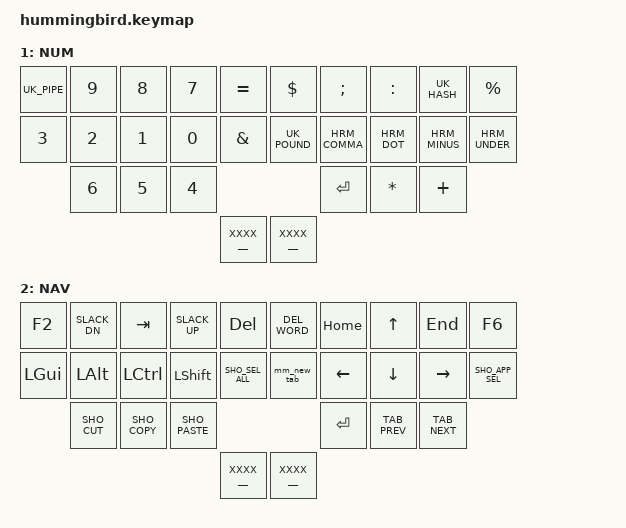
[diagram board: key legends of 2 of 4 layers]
/*
 * Copyright (c) 2020 The ZMK Contributors
 *
 * SPDX-License-Identifier: MIT
 */

//						KEY POSITIONS
//		 0	 1	 2	 3	 4		 5	 6	 7	 8	 9
//		10	11	12	13	14		15	16	17	18	19 
//			20	21	22				23	24	25
//					26	27		28	29
//
//		 K	 W	 C	 D	 B		 J	 L	 U	 Y	 '
//		 A	 R	 S	 T	 P		 X	 N	 H	 I	 O 
//			 V	 F	 G				 M	 Q	 Z
//					ESC	SPA		 E	BSPC

// nothing using Grave3 at the mo

#include "defines.dtsi"
#include "behaviors.dtsi"
#include "combos.dtsi"
#include "macros.dtsi"

// capsword
/ {
	keymap {
		compatible = "zmk,keymap";

		Default_layer {
            label = "DEF";
            bindings = <
				&kp K		&kp W		&kp C		&kp D		&kp B				&kp J		&kp L		&kp U		&kp Y		&mm_sqt_sqt
				HRM_A		HRM_R		HRM_S		HRM_T		&kp P				&kp X		HRM_N		HRM_H		HRM_I		HRM_O
							&kp V		&kp F		&kp G                                       &kp M		&kp Q		&kp Z

																&lt NAV SPACE		&lt NUM E
			>;
		};

        Number_layer {
            label = "NUM";
			bindings = <
				UK_PIPE		&kp N9		&kp N8		&kp N7		&kp EQUAL			&kp DOLLAR	&kp SEMI	&kp COLON	UK_HASH		&kp PERCENT
				&kp N3		&kp N2		&kp N1		&kp N0		&kp AMPS			UK_POUND	HRM_COMMA 	HRM_DOT		HRM_MINUS	HRM_UNDER
							&kp N6		&kp N5		&kp N4										&kp ENTER 	&kp STAR	&kp PLUS

																___XXXX___			___XXXX___
			>;
		};

        Navigation_layer {
            label = "NAV";
			bindings = <
				&kp F2		SLACK_DN	&kp TAB		SLACK_UP	&kp DEL				DEL_WORD	&kp HOME	&kp UP		&kp END		&kp F6
				&kp LGUI   	&kp LALT	&kp LCTL    &kp LSHIFT	SHO_SEL_ALL			&mm_new_tab	&kp LEFT	&kp DOWN	&kp RIGHT	SHO_APP_SEL
							SHO_CUT		SHO_COPY	SHO_PASTE                                   &kp ENTER	TAB_PREV	TAB_NEXT

																___XXXX___			___XXXX___
			>;
		};
 
		Misc_layer {
            label = "MIS";
            bindings = <
				&bootloader	&kp C_PREV	&kp C_PLAY	&kp C_NEXT	&kp F11				&kp F12		VOL_DOWN	VOL_MUTE	VOL_UP		KILL
				&bt BT_CLR	CON_THREE	CON_TWO		CON_ONE		CAD					SCREEN_SHOT	A_INBOX		A_SLACK		A_GLADMIN	A_BULLHORN
							&kp CARET	UK_TILDE	UK_GRAVE									A_CALENDAR	DESK_L		DESK_R
				
																___XXXX___			___XXXX___
			>;
		};
	};
};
